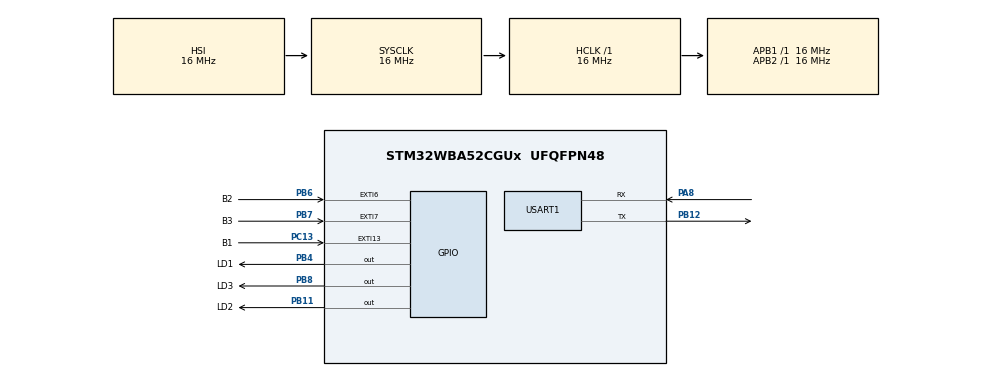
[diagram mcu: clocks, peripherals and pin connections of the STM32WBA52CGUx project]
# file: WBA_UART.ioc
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CORTEX_M33_NS.userName=CORTEX_M33
Mcu.Family=STM32WBA
Mcu.Name=STM32WBA52CGUx
Mcu.Package=UFQFPN48
NVIC.EXTI13_IRQn=true\:0\:0\:false\:false\:true\:true\:true\:true
NVIC.EXTI6_IRQn=true\:0\:0\:false\:false\:true\:true\:true\:true
NVIC.EXTI7_IRQn=true\:0\:0\:false\:false\:true\:true\:true\:true
NVIC.PriorityGroup=NVIC_PRIORITYGROUP_4
OSC_IN.Signal=RCC_OSC_IN
OSC_OUT.Signal=RCC_OSC_OUT
PA13\ (JTMS/SWDIO).Signal=DEBUG_JTMS-SWDIO
PA14\ (JTCK/SWCLK).Signal=DEBUG_JTCK-SWCLK
PA8.Mode=Asynchronous
PA8.Signal=USART1_RX
PB11.GPIO_Label=LD2
PB11.GPIO_Speed=GPIO_SPEED_FREQ_HIGH
PB11.Signal=GPIO_Output
PB12.Mode=Asynchronous
PB12.Signal=USART1_TX
PB4\ (NJTRST).GPIO_Label=LD1
PB4\ (NJTRST).GPIO_Speed=GPIO_SPEED_FREQ_HIGH
PB4\ (NJTRST).Signal=GPIO_Output
PB6.GPIO_Label=B2
PB6.Signal=GPXTI6
PB7.GPIO_Label=B3
PB7.Signal=GPXTI7
PB8.GPIO_Label=LD3
PB8.GPIO_Speed=GPIO_SPEED_FREQ_HIGH
PB8.Signal=GPIO_Output
PC13.GPIO_Label=B1
PC13.Signal=GPXTI13
PC14-OSC32_IN.Signal=RCC_OSC32_IN
PC15-OSC32_OUT.Signal=RCC_OSC32_OUT
ProjectManager.HeapSize=0x200
ProjectManager.StackSize=0x400
ProjectManager.TargetToolchain=STM32CubeIDE
RCC.ADCFreq_Value=16000000
RCC.AHBFreq_Value=16000000
RCC.APB1Freq_Value=16000000
RCC.APB1TimFreq_Value=16000000
RCC.APB2Freq_Value=16000000
RCC.APB2TimFreq_Value=16000000
RCC.CortexFreq_Value=2000000
RCC.HCLKFreq_Value=16000000
RCC.HSE_VALUE=32000000
RCC.HSI_VALUE=16000000
RCC.LSE_VALUE=32768
RCC.PWR_Regulator_Voltage_Scale=PWR_REGULATOR_VOLTAGE_SCALE1
RCC.SYSCLKFreq_VALUE=16000000
RCC.VCOOutputFreq_Value=2064000000
USART1.VirtualMode-Asynchronous=VM_ASYNC
VP_ICACHE_VS_ICACHE.Mode=DirectMappedCache
VP_PWR_VS_SECSignals.Mode=Security/Privilege
board=NUCLEO-WBA52CG

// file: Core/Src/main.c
/* USER CODE BEGIN Header */
/**
  ******************************************************************************
  * @file           : main.c
  * @brief          : Main program body
  ******************************************************************************
  * @attention
  *
  * Copyright (c) 2023 STMicroelectronics.
  * All rights reserved.
  *
  * This software is licensed under terms that can be found in the LICENSE file
  * in the root directory of this software component.
  * If no LICENSE file comes with this software, it is provided AS-IS.
  *
  ******************************************************************************
  */
/* USER CODE END Header */
#include "main.h"

UART_HandleTypeDef huart1;

/* USER CODE BEGIN PV */
uint8_t buffer[]={"Hello STM32WBA\r\n"};
/* USER CODE END PV */

void SystemClock_Config(void);
void PeriphCommonClock_Config(void);
static void MX_GPIO_Init(void);
static void MX_ICACHE_Init(void);
static void MX_USART1_UART_Init(void);

int main(void)
{

  /* MCU Configuration--------------------------------------------------------*/

  /* Reset of all peripherals, Initializes the Flash interface and the Systick. */
  HAL_Init();

  /* Configure the system clock */
  SystemClock_Config();

/* Configure the peripherals common clocks */
  PeriphCommonClock_Config();

  /* Initialize all configured peripherals */
  MX_GPIO_Init();
  MX_ICACHE_Init();
  MX_USART1_UART_Init();
  /* USER CODE BEGIN 2 */
  HAL_GPIO_WritePin(LD1_GPIO_Port, LD1_Pin, 1);
  /* USER CODE END 2 */

  /* Infinite loop */
  while (1)
  {

    /* USER CODE BEGIN 3 */
	  HAL_GPIO_TogglePin(LD1_GPIO_Port, LD1_Pin);
	  HAL_GPIO_TogglePin(LD2_GPIO_Port, LD2_Pin);
	  HAL_GPIO_TogglePin(LD3_GPIO_Port, LD3_Pin);
	  HAL_UART_Transmit(&huart1, buffer, 15, 200);
	  HAL_Delay(250);
  }
  /* USER CODE END 3 */
}

void SystemClock_Config(void)
{
  RCC_OscInitTypeDef RCC_OscInitStruct = {0};
  RCC_ClkInitTypeDef RCC_ClkInitStruct = {0};

  /** Configure the main internal regulator output voltage
  */
  if (HAL_PWREx_ControlVoltageScaling(PWR_REGULATOR_VOLTAGE_SCALE1) != HAL_OK)
  {
    Error_Handler();
  }

  /** Initializes the CPU, AHB and APB busses clocks
  */
  RCC_OscInitStruct.OscillatorType = RCC_OSCILLATORTYPE_HSI;
  RCC_OscInitStruct.HSIState = RCC_HSI_ON;
  RCC_OscInitStruct.HSICalibrationValue = RCC_HSICALIBRATION_DEFAULT;
  RCC_OscInitStruct.PLL1.PLLState = RCC_PLL_NONE;
  if (HAL_RCC_OscConfig(&RCC_OscInitStruct) != HAL_OK)
  {
    Error_Handler();
  }

  /** Initializes the CPU, AHB and APB busses clocks
  */
  RCC_ClkInitStruct.ClockType = RCC_CLOCKTYPE_HCLK|RCC_CLOCKTYPE_SYSCLK
                              |RCC_CLOCKTYPE_PCLK1|RCC_CLOCKTYPE_PCLK2
                              |RCC_CLOCKTYPE_PCLK7|RCC_CLOCKTYPE_HCLK5;
  RCC_ClkInitStruct.SYSCLKSource = RCC_SYSCLKSOURCE_HSI;
  RCC_ClkInitStruct.AHBCLKDivider = RCC_SYSCLK_DIV1;
  RCC_ClkInitStruct.APB1CLKDivider = RCC_HCLK_DIV1;
  RCC_ClkInitStruct.APB2CLKDivider = RCC_HCLK_DIV1;
  RCC_ClkInitStruct.APB7CLKDivider = RCC_HCLK_DIV1;
  RCC_ClkInitStruct.AHB5_PLL1_CLKDivider = RCC_SYSCLK_PLL1_DIV1;
  RCC_ClkInitStruct.AHB5_HSEHSI_CLKDivider = RCC_SYSCLK_HSEHSI_DIV1;

  if (HAL_RCC_ClockConfig(&RCC_ClkInitStruct, FLASH_LATENCY_0) != HAL_OK)
  {
    Error_Handler();
  }
}

void PeriphCommonClock_Config(void)
{
  RCC_PeriphCLKInitTypeDef PeriphClkInit = {0};

  /** Initializes the peripherals clock
  */
  PeriphClkInit.PeriphClockSelection = RCC_PERIPHCLK_SYSTICK;
  PeriphClkInit.SystickClockSelection = RCC_SYSTICKCLKSOURCE_HCLK_DIV8;
  if (HAL_RCCEx_PeriphCLKConfig(&PeriphClkInit) != HAL_OK)
  {
    Error_Handler();
  }
}

static void MX_ICACHE_Init(void)
{

  /** Enable instruction cache in 1-way (direct mapped cache)
  */
  if (HAL_ICACHE_ConfigAssociativityMode(ICACHE_1WAY) != HAL_OK)
  {
    Error_Handler();
  }
  if (HAL_ICACHE_Enable() != HAL_OK)
  {
    Error_Handler();
  }

}

static void MX_USART1_UART_Init(void)
{

  huart1.Instance = USART1;
  huart1.Init.BaudRate = 115200;
  huart1.Init.WordLength = UART_WORDLENGTH_8B;
  huart1.Init.StopBits = UART_STOPBITS_1;
  huart1.Init.Parity = UART_PARITY_NONE;
  huart1.Init.Mode = UART_MODE_TX_RX;
  huart1.Init.HwFlowCtl = UART_HWCONTROL_NONE;
  huart1.Init.OverSampling = UART_OVERSAMPLING_16;
  huart1.Init.OneBitSampling = UART_ONE_BIT_SAMPLE_DISABLE;
  huart1.Init.ClockPrescaler = UART_PRESCALER_DIV1;
  huart1.AdvancedInit.AdvFeatureInit = UART_ADVFEATURE_NO_INIT;
  if (HAL_UART_Init(&huart1) != HAL_OK)
  {
    Error_Handler();
  }
  if (HAL_UARTEx_SetTxFifoThreshold(&huart1, UART_TXFIFO_THRESHOLD_1_8) != HAL_OK)
  {
    Error_Handler();
  }
  if (HAL_UARTEx_SetRxFifoThreshold(&huart1, UART_RXFIFO_THRESHOLD_1_8) != HAL_OK)
  {
    Error_Handler();
  }
  if (HAL_UARTEx_DisableFifoMode(&huart1) != HAL_OK)
  {
    Error_Handler();
  }

}

static void MX_GPIO_Init(void)
{
  GPIO_InitTypeDef GPIO_InitStruct = {0};

  /* GPIO Ports Clock Enable */
  __HAL_RCC_GPIOB_CLK_ENABLE();
  __HAL_RCC_GPIOA_CLK_ENABLE();
  __HAL_RCC_GPIOC_CLK_ENABLE();

  /*Configure GPIO pin Output Level */
  HAL_GPIO_WritePin(GPIOB, LD2_Pin|LD3_Pin|LD1_Pin, GPIO_PIN_RESET);

  /*Configure GPIO pins : LD2_Pin LD3_Pin LD1_Pin */
  GPIO_InitStruct.Pin = LD2_Pin|LD3_Pin|LD1_Pin;
  GPIO_InitStruct.Mode = GPIO_MODE_OUTPUT_PP;
  GPIO_InitStruct.Pull = GPIO_NOPULL;
  GPIO_InitStruct.Speed = GPIO_SPEED_FREQ_HIGH;
  HAL_GPIO_Init(GPIOB, &GPIO_InitStruct);

  /*Configure GPIO pin : B1_Pin */
  GPIO_InitStruct.Pin = B1_Pin;
  GPIO_InitStruct.Mode = GPIO_MODE_IT_RISING;
  GPIO_InitStruct.Pull = GPIO_NOPULL;
  HAL_GPIO_Init(B1_GPIO_Port, &GPIO_InitStruct);

  /*Configure GPIO pins : B3_Pin B2_Pin */
  GPIO_InitStruct.Pin = B3_Pin|B2_Pin;
  GPIO_InitStruct.Mode = GPIO_MODE_IT_RISING;
  GPIO_InitStruct.Pull = GPIO_NOPULL;
  HAL_GPIO_Init(GPIOB, &GPIO_InitStruct);

  /* EXTI interrupt init*/
  HAL_NVIC_SetPriority(EXTI6_IRQn, 0, 0);
  HAL_NVIC_EnableIRQ(EXTI6_IRQn);

  HAL_NVIC_SetPriority(EXTI7_IRQn, 0, 0);
  HAL_NVIC_EnableIRQ(EXTI7_IRQn);

  HAL_NVIC_SetPriority(EXTI13_IRQn, 0, 0);
  HAL_NVIC_EnableIRQ(EXTI13_IRQn);

}

void Error_Handler(void)
{
  __disable_irq();
  while (1)
  {
  }
}
